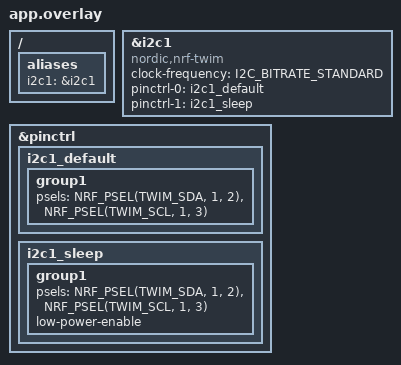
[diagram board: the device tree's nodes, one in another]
/ {
    aliases {
        i2c1 = &i2c1;
    };
};

/* Enable I2C1 (TWIM1) with pinctrl — SDA=P0.02, SCL=P0.03 */
&i2c1 {
    compatible = "nordic,nrf-twim";
    status = "okay";
    clock-frequency = <I2C_BITRATE_STANDARD>; /* 100 kHz */
    pinctrl-0 = <&i2c1_default>;
    pinctrl-1 = <&i2c1_sleep>;
    pinctrl-names = "default", "sleep";
};

/* Pinctrl group definitions */
&pinctrl {
    i2c1_default: i2c1_default {
        group1 {
            psels = <NRF_PSEL(TWIM_SDA, 1, 2)>,  /* SDA = P0.02 */
                    <NRF_PSEL(TWIM_SCL, 1, 3)>;  /* SCL = P0.03 */
        };
    };

    i2c1_sleep: i2c1_sleep {
        group1 {
            psels = <NRF_PSEL(TWIM_SDA, 1, 2)>,
                    <NRF_PSEL(TWIM_SCL, 1, 3)>;
            low-power-enable;
        };
    };
};
